AUTOSAR XML (schema 00048)
package /AUTOLIV/SoftwareComponents/PRE
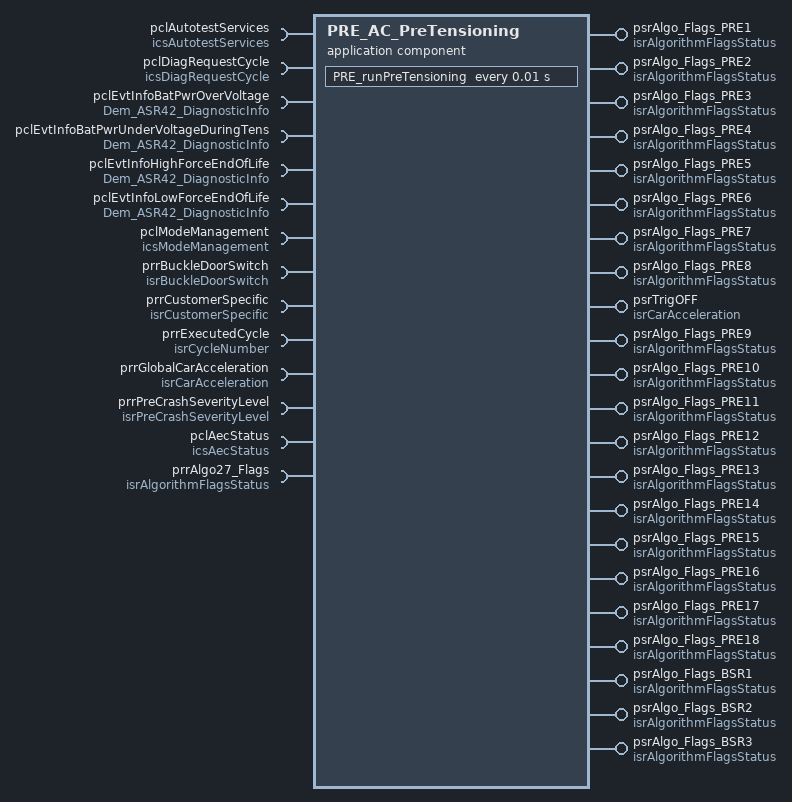
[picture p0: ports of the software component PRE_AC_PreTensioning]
  application sw component type PRE_AC_PreTensioning
    12 x require port:
      pclAutotestServices: required-com-specs=[GetLastCriticalAutotestID, GetTestResult], required-interface=icsAutotestServices
      pclDiagRequestCycle: required-com-specs=[ClearDiagRequestCycle, GetDiagRequestCycle], required-interface=icsDiagRequestCycle
      pclEvtInfoBatPwrOverVoltage: required-interface=Dem_ASR42_DiagnosticInfo
        required-com-specs:
          GetDTCOfEvent
          GetDebouncingOfEvent
          GetEventExtendedDataRecord
          GetEventExtendedDataRecordEx
          GetEventFailed
          GetEventFreezeFrameData
          GetEventFreezeFrameDataEx
          GetEventStatus
          GetEventTested
          GetFaultDetectionCounter
      pclEvtInfoBatPwrUnderVoltageDuringTens: required-interface=Dem_ASR42_DiagnosticInfo
        required-com-specs:
          GetDTCOfEvent
          GetDebouncingOfEvent
          GetEventExtendedDataRecord
          GetEventExtendedDataRecordEx
          GetEventFailed
          GetEventFreezeFrameData
          GetEventFreezeFrameDataEx
          GetEventStatus
          GetEventTested
          GetFaultDetectionCounter
      pclEvtInfoHighForceEndOfLife: required-interface=Dem_ASR42_DiagnosticInfo
        required-com-specs:
          GetDTCOfEvent
          GetDebouncingOfEvent
          GetEventExtendedDataRecord
          GetEventExtendedDataRecordEx
          GetEventFailed
          GetEventFreezeFrameData
          GetEventFreezeFrameDataEx
          GetEventStatus
          GetEventTested
          GetFaultDetectionCounter
      pclEvtInfoLowForceEndOfLife: required-interface=Dem_ASR42_DiagnosticInfo
        required-com-specs:
          GetDTCOfEvent
          GetDebouncingOfEvent
          GetEventExtendedDataRecord
          GetEventExtendedDataRecordEx
          GetEventFailed
          GetEventFreezeFrameData
          GetEventFreezeFrameDataEx
          GetEventStatus
          GetEventTested
          GetFaultDetectionCounter
      pclModeManagement: client-com-spec=CheckModeStatus, required-interface=icsModeManagement
      prrBuckleDoorSwitch: required-interface=isrBuckleDoorSwitch
        required-com-specs:
          data-element=u8BuckleSwitch, init-value=constant-reference=APPLINIT_KB8_BUCKLE_SWITCH_CLOSED
          data-element=u8DoorSwitch, init-value=constant-reference=APPLINIT_KU8_DOOR_SWITCH_STATUS_NOT_DEFINED
      prrCustomerSpecific: required-interface=isrCustomerSpecific
        required-com-specs:
          data-element=b8HardReleaseRequest
          data-element=b8IsCarCrankingActive, init-value=constant-reference=APPLINIT_KB8_CAR_CRANKING_ACTIVE_TRUE
          data-element=b8IsCarCrashDetected, init-value=constant-reference=APPLINIT_KB8_CAR_CRASH_DETECTED_FALSE
          data-element=b8IsTrigOffEventAllowed
          data-element=b8PreCrashRequestEnable, init-value=constant-reference=APPLINIT_KB8_BOOLEAN_FALSE
          data-element=u8BeltSlackStatus, init-value=constant-reference=APPLINIT_KU8_BELT_SLACK_STATUS_NOT_DEFINED
          data-element=u8HapticRequest, init-value=constant-reference=APPLINIT_KU8_HAPTIC_REQUEST_NO
          data-element=u8PreCrashRequest, init-value=constant-reference=APPLINIT_KU8_PRE_CRASH_REQUEST_NO_REQUEST
          data-element=u8TriggerRequest
          data-element=b8SignalRelInhibition
      prrExecutedCycle: nonqueued-receiver-com-spec{data-element=u8CycleNumber, init-value=constant-reference=APPLINIT_KU8_CYCLE_NUMBER_NONE}, required-interface=isrCycleNumber
      prrGlobalCarAcceleration: nonqueued-receiver-com-spec{data-element=b8IsCarAccelerationLow, init-value=constant-reference=APPLINIT_KB8_CAR_ACCEL_LOW_TRUE}, required-interface=isrCarAcceleration
      prrPreCrashSeverityLevel: nonqueued-receiver-com-spec{data-element=u8PreCrashSeverityLevel, init-value=constant-reference=APPLINIT_KU8_PRE_CRASH_SEVERITY_LEVEL_NO}, required-interface=isrPreCrashSeverityLevel
    9 x provide port:
      psrAlgo_Flags_PRE1: provided-interface=isrAlgorithmFlagsStatus
        provided-com-specs:
          data-element=b8InterruptFlag, init-value=constant-reference=APPLINIT_KB8_ALGO_FLAG_FALSE
          data-element=b8PreActivationFlag, uses-end-to-end-protection=true, init-value=constant-reference=APPLINIT_KB8_ALGO_FLAG_FALSE
          data-element=b8PreConditionsFlag, uses-end-to-end-protection=true, init-value=constant-reference=APPLINIT_KB8_ALGO_FLAG_FALSE
          data-element=b8TriggerFlag, uses-end-to-end-protection=true, init-value=constant-reference=APPLINIT_KB8_ALGO_FLAG_FALSE
          data-element=u8TriggeringSource, uses-end-to-end-protection=true, init-value=constant-reference=APPLINIT_KU8_TRIGGERING_SOURCE_NO
      psrAlgo_Flags_PRE2: provided-interface=isrAlgorithmFlagsStatus
        provided-com-specs:
          data-element=b8InterruptFlag, uses-end-to-end-protection=true, init-value=constant-reference=APPLINIT_KB8_ALGO_FLAG_FALSE
          data-element=b8PreActivationFlag, uses-end-to-end-protection=true, init-value=constant-reference=APPLINIT_KB8_ALGO_FLAG_FALSE
          data-element=b8PreConditionsFlag, uses-end-to-end-protection=true, init-value=constant-reference=APPLINIT_KB8_ALGO_FLAG_FALSE
          data-element=b8TriggerFlag, uses-end-to-end-protection=true, init-value=constant-reference=APPLINIT_KB8_ALGO_FLAG_FALSE
          data-element=u8TriggeringSource, uses-end-to-end-protection=true, init-value=constant-reference=APPLINIT_KU8_TRIGGERING_SOURCE_NO
      psrAlgo_Flags_PRE3: provided-interface=isrAlgorithmFlagsStatus
        provided-com-specs:
          data-element=b8InterruptFlag, uses-end-to-end-protection=true, init-value=constant-reference=APPLINIT_KB8_ALGO_FLAG_FALSE
          data-element=b8PreActivationFlag, uses-end-to-end-protection=true, init-value=constant-reference=APPLINIT_KB8_ALGO_FLAG_FALSE
          data-element=b8PreConditionsFlag, uses-end-to-end-protection=true, init-value=constant-reference=APPLINIT_KB8_ALGO_FLAG_FALSE
          data-element=b8TriggerFlag, uses-end-to-end-protection=true, init-value=constant-reference=APPLINIT_KB8_ALGO_FLAG_FALSE
          data-element=u8TriggeringSource, uses-end-to-end-protection=true, init-value=constant-reference=APPLINIT_KU8_TRIGGERING_SOURCE_NO
      psrAlgo_Flags_PRE4: provided-interface=isrAlgorithmFlagsStatus
        provided-com-specs:
          data-element=b8InterruptFlag, uses-end-to-end-protection=true, init-value=constant-reference=APPLINIT_KB8_ALGO_FLAG_FALSE
          data-element=b8PreActivationFlag, uses-end-to-end-protection=true, init-value=constant-reference=APPLINIT_KB8_ALGO_FLAG_FALSE
          data-element=b8PreConditionsFlag, uses-end-to-end-protection=true, init-value=constant-reference=APPLINIT_KB8_ALGO_FLAG_FALSE
          data-element=b8TriggerFlag, uses-end-to-end-protection=true, init-value=constant-reference=APPLINIT_KB8_ALGO_FLAG_FALSE
          data-element=u8TriggeringSource, uses-end-to-end-protection=true, init-value=constant-reference=APPLINIT_KU8_TRIGGERING_SOURCE_NO
      psrAlgo_Flags_PRE5: provided-interface=isrAlgorithmFlagsStatus
        provided-com-specs:
          data-element=b8InterruptFlag, uses-end-to-end-protection=true, init-value=constant-reference=APPLINIT_KB8_ALGO_FLAG_FALSE
          data-element=b8PreActivationFlag, uses-end-to-end-protection=true, init-value=constant-reference=APPLINIT_KB8_ALGO_FLAG_FALSE
          data-element=b8PreConditionsFlag, uses-end-to-end-protection=true, init-value=constant-reference=APPLINIT_KB8_ALGO_FLAG_FALSE
          data-element=b8TriggerFlag, uses-end-to-end-protection=true, init-value=constant-reference=APPLINIT_KB8_ALGO_FLAG_FALSE
          data-element=u8TriggeringSource, uses-end-to-end-protection=true, init-value=constant-reference=APPLINIT_KU8_TRIGGERING_SOURCE_NO
      psrAlgo_Flags_PRE6: provided-interface=isrAlgorithmFlagsStatus
        provided-com-specs:
          data-element=b8InterruptFlag, uses-end-to-end-protection=true, init-value=constant-reference=APPLINIT_KB8_ALGO_FLAG_FALSE
          data-element=b8PreActivationFlag, uses-end-to-end-protection=true, init-value=constant-reference=APPLINIT_KB8_ALGO_FLAG_FALSE
          data-element=b8PreConditionsFlag, uses-end-to-end-protection=true, init-value=constant-reference=APPLINIT_KB8_ALGO_FLAG_FALSE
          data-element=b8TriggerFlag, uses-end-to-end-protection=true, init-value=constant-reference=APPLINIT_KB8_ALGO_FLAG_FALSE
          data-element=u8TriggeringSource, uses-end-to-end-protection=true, init-value=constant-reference=APPLINIT_KU8_TRIGGERING_SOURCE_NO
      psrAlgo_Flags_PRE7: provided-interface=isrAlgorithmFlagsStatus
        provided-com-specs:
          data-element=b8InterruptFlag, uses-end-to-end-protection=true, init-value=constant-reference=APPLINIT_KB8_ALGO_FLAG_FALSE
          data-element=b8PreActivationFlag, uses-end-to-end-protection=true, init-value=constant-reference=APPLINIT_KB8_ALGO_FLAG_FALSE
          data-element=b8PreConditionsFlag, uses-end-to-end-protection=true, init-value=constant-reference=APPLINIT_KB8_ALGO_FLAG_FALSE
          data-element=b8TriggerFlag, uses-end-to-end-protection=true, init-value=constant-reference=APPLINIT_KB8_ALGO_FLAG_FALSE
          data-element=u8TriggeringSource, uses-end-to-end-protection=true, init-value=constant-reference=APPLINIT_KU8_TRIGGERING_SOURCE_NO
      psrAlgo_Flags_PRE8: provided-interface=isrAlgorithmFlagsStatus
        provided-com-specs:
          data-element=b8InterruptFlag, uses-end-to-end-protection=true, init-value=constant-reference=APPLINIT_KB8_ALGO_FLAG_FALSE
          data-element=b8PreActivationFlag, uses-end-to-end-protection=true, init-value=constant-reference=APPLINIT_KB8_ALGO_FLAG_FALSE
          data-element=b8PreConditionsFlag, uses-end-to-end-protection=true, init-value=constant-reference=APPLINIT_KB8_ALGO_FLAG_FALSE
          data-element=b8TriggerFlag, uses-end-to-end-protection=true, init-value=constant-reference=APPLINIT_KB8_ALGO_FLAG_FALSE
          data-element=u8TriggeringSource, uses-end-to-end-protection=true, init-value=constant-reference=APPLINIT_KU8_TRIGGERING_SOURCE_NO
      psrTrigOFF: nonqueued-sender-com-spec{data-element=b8IsCarAccelerationLow, uses-end-to-end-protection=true, init-value=constant-reference=APPLINIT_KB8_CAR_ACCEL_LOW_TRUE}, provided-interface=isrCarAcceleration
    require port pclAecStatus: required-interface=icsAecStatus
      required-com-specs:
        SetAecEvent
        GetNumberOfImplementedAec
        GetAecStatus
        GetAecQualificationCount
        GetAecNvpBlockRecordingStatus
        GetAecGroupsStatus
        GetAecDeskillThrs
    13 x provide port, all with provided-interface=isrAlgorithmFlagsStatus:
      psrAlgo_Flags_PRE9
        provided-com-specs:
          data-element=b8InterruptFlag, init-value=constant-reference=APPLINIT_KB8_ALGO_FLAG_FALSE
          data-element=b8PreActivationFlag, uses-end-to-end-protection=true, init-value=constant-reference=APPLINIT_KB8_ALGO_FLAG_FALSE
          data-element=b8PreConditionsFlag, uses-end-to-end-protection=true, init-value=constant-reference=APPLINIT_KB8_ALGO_FLAG_FALSE
          data-element=b8TriggerFlag, uses-end-to-end-protection=true, init-value=constant-reference=APPLINIT_KB8_ALGO_FLAG_FALSE
          data-element=u8TriggeringSource, uses-end-to-end-protection=true, init-value=constant-reference=APPLINIT_KU8_TRIGGERING_SOURCE_NO
      psrAlgo_Flags_PRE10
        provided-com-specs:
          data-element=b8InterruptFlag, uses-end-to-end-protection=true, init-value=constant-reference=APPLINIT_KB8_ALGO_FLAG_FALSE
          data-element=b8PreActivationFlag, uses-end-to-end-protection=true, init-value=constant-reference=APPLINIT_KB8_ALGO_FLAG_FALSE
          data-element=b8PreConditionsFlag, uses-end-to-end-protection=true, init-value=constant-reference=APPLINIT_KB8_ALGO_FLAG_FALSE
          data-element=b8TriggerFlag, uses-end-to-end-protection=true, init-value=constant-reference=APPLINIT_KB8_ALGO_FLAG_FALSE
          data-element=u8TriggeringSource, uses-end-to-end-protection=true, init-value=constant-reference=APPLINIT_KU8_TRIGGERING_SOURCE_NO
      psrAlgo_Flags_PRE11
        provided-com-specs:
          data-element=b8InterruptFlag, uses-end-to-end-protection=true, init-value=constant-reference=APPLINIT_KB8_ALGO_FLAG_FALSE
          data-element=b8PreActivationFlag, uses-end-to-end-protection=true, init-value=constant-reference=APPLINIT_KB8_ALGO_FLAG_FALSE
          data-element=b8PreConditionsFlag, uses-end-to-end-protection=true, init-value=constant-reference=APPLINIT_KB8_ALGO_FLAG_FALSE
          data-element=b8TriggerFlag, uses-end-to-end-protection=true, init-value=constant-reference=APPLINIT_KB8_ALGO_FLAG_FALSE
          data-element=u8TriggeringSource, uses-end-to-end-protection=true, init-value=constant-reference=APPLINIT_KU8_TRIGGERING_SOURCE_NO
      psrAlgo_Flags_PRE12
        provided-com-specs:
          data-element=b8InterruptFlag, uses-end-to-end-protection=true, init-value=constant-reference=APPLINIT_KB8_ALGO_FLAG_FALSE
          data-element=b8PreActivationFlag, uses-end-to-end-protection=true, init-value=constant-reference=APPLINIT_KB8_ALGO_FLAG_FALSE
          data-element=b8PreConditionsFlag, uses-end-to-end-protection=true, init-value=constant-reference=APPLINIT_KB8_ALGO_FLAG_FALSE
          data-element=b8TriggerFlag, uses-end-to-end-protection=true, init-value=constant-reference=APPLINIT_KB8_ALGO_FLAG_FALSE
          data-element=u8TriggeringSource, uses-end-to-end-protection=true, init-value=constant-reference=APPLINIT_KU8_TRIGGERING_SOURCE_NO
      psrAlgo_Flags_PRE13
        provided-com-specs:
          data-element=b8InterruptFlag, uses-end-to-end-protection=true, init-value=constant-reference=APPLINIT_KB8_ALGO_FLAG_FALSE
          data-element=b8PreActivationFlag, uses-end-to-end-protection=true, init-value=constant-reference=APPLINIT_KB8_ALGO_FLAG_FALSE
          data-element=b8PreConditionsFlag, uses-end-to-end-protection=true, init-value=constant-reference=APPLINIT_KB8_ALGO_FLAG_FALSE
          data-element=b8TriggerFlag, uses-end-to-end-protection=true, init-value=constant-reference=APPLINIT_KB8_ALGO_FLAG_FALSE
          data-element=u8TriggeringSource, uses-end-to-end-protection=true, init-value=constant-reference=APPLINIT_KU8_TRIGGERING_SOURCE_NO
      psrAlgo_Flags_PRE14
        provided-com-specs:
          data-element=b8InterruptFlag, uses-end-to-end-protection=true, init-value=constant-reference=APPLINIT_KB8_ALGO_FLAG_FALSE
          data-element=b8PreActivationFlag, uses-end-to-end-protection=true, init-value=constant-reference=APPLINIT_KB8_ALGO_FLAG_FALSE
          data-element=b8PreConditionsFlag, uses-end-to-end-protection=true, init-value=constant-reference=APPLINIT_KB8_ALGO_FLAG_FALSE
          data-element=b8TriggerFlag, uses-end-to-end-protection=true, init-value=constant-reference=APPLINIT_KB8_ALGO_FLAG_FALSE
          data-element=u8TriggeringSource, uses-end-to-end-protection=true, init-value=constant-reference=APPLINIT_KU8_TRIGGERING_SOURCE_NO
      psrAlgo_Flags_PRE15
        provided-com-specs:
          data-element=b8InterruptFlag, uses-end-to-end-protection=true, init-value=constant-reference=APPLINIT_KB8_ALGO_FLAG_FALSE
          data-element=b8PreActivationFlag, uses-end-to-end-protection=true, init-value=constant-reference=APPLINIT_KB8_ALGO_FLAG_FALSE
          data-element=b8PreConditionsFlag, uses-end-to-end-protection=true, init-value=constant-reference=APPLINIT_KB8_ALGO_FLAG_FALSE
          data-element=b8TriggerFlag, uses-end-to-end-protection=true, init-value=constant-reference=APPLINIT_KB8_ALGO_FLAG_FALSE
          data-element=u8TriggeringSource, uses-end-to-end-protection=true, init-value=constant-reference=APPLINIT_KU8_TRIGGERING_SOURCE_NO
      psrAlgo_Flags_PRE16
        provided-com-specs:
          data-element=b8InterruptFlag, uses-end-to-end-protection=true, init-value=constant-reference=APPLINIT_KB8_ALGO_FLAG_FALSE
          data-element=b8PreActivationFlag, uses-end-to-end-protection=true, init-value=constant-reference=APPLINIT_KB8_ALGO_FLAG_FALSE
          data-element=b8PreConditionsFlag, uses-end-to-end-protection=true, init-value=constant-reference=APPLINIT_KB8_ALGO_FLAG_FALSE
          data-element=b8TriggerFlag, uses-end-to-end-protection=true, init-value=constant-reference=APPLINIT_KB8_ALGO_FLAG_FALSE
          data-element=u8TriggeringSource, uses-end-to-end-protection=true, init-value=constant-reference=APPLINIT_KU8_TRIGGERING_SOURCE_NO
      psrAlgo_Flags_PRE17
        provided-com-specs:
          data-element=b8InterruptFlag, uses-end-to-end-protection=true, init-value=constant-reference=APPLINIT_KB8_ALGO_FLAG_FALSE
          data-element=b8PreActivationFlag, uses-end-to-end-protection=true, init-value=constant-reference=APPLINIT_KB8_ALGO_FLAG_FALSE
          data-element=b8PreConditionsFlag, uses-end-to-end-protection=true, init-value=constant-reference=APPLINIT_KB8_ALGO_FLAG_FALSE
          data-element=b8TriggerFlag, uses-end-to-end-protection=true, init-value=constant-reference=APPLINIT_KB8_ALGO_FLAG_FALSE
          data-element=u8TriggeringSource, uses-end-to-end-protection=true, init-value=constant-reference=APPLINIT_KU8_TRIGGERING_SOURCE_NO
      psrAlgo_Flags_PRE18
        provided-com-specs:
          data-element=b8InterruptFlag, uses-end-to-end-protection=true, init-value=constant-reference=APPLINIT_KB8_ALGO_FLAG_FALSE
          data-element=b8PreActivationFlag, uses-end-to-end-protection=true, init-value=constant-reference=APPLINIT_KB8_ALGO_FLAG_FALSE
          data-element=b8PreConditionsFlag, uses-end-to-end-protection=true, init-value=constant-reference=APPLINIT_KB8_ALGO_FLAG_FALSE
          data-element=b8TriggerFlag, uses-end-to-end-protection=true, init-value=constant-reference=APPLINIT_KB8_ALGO_FLAG_FALSE
          data-element=u8TriggeringSource, uses-end-to-end-protection=true, init-value=constant-reference=APPLINIT_KU8_TRIGGERING_SOURCE_NO
      psrAlgo_Flags_BSR1
        provided-com-specs:
          data-element=b8InterruptFlag, init-value=constant-reference=APPLINIT_KB8_ALGO_FLAG_FALSE
          data-element=b8PreActivationFlag, init-value=constant-reference=APPLINIT_KB8_ALGO_FLAG_FALSE
          data-element=b8PreConditionsFlag, init-value=constant-reference=APPLINIT_KB8_ALGO_FLAG_FALSE
          data-element=b8TriggerFlag, init-value=constant-reference=APPLINIT_KB8_ALGO_FLAG_FALSE
          data-element=u8TriggeringSource, init-value=constant-reference=APPLINIT_KU8_TRIGGERING_SOURCE_NO
      psrAlgo_Flags_BSR2
        provided-com-specs:
          data-element=b8InterruptFlag, uses-end-to-end-protection=true, init-value=constant-reference=APPLINIT_KB8_ALGO_FLAG_FALSE
          data-element=b8PreActivationFlag, uses-end-to-end-protection=true, init-value=constant-reference=APPLINIT_KB8_ALGO_FLAG_FALSE
          data-element=b8PreConditionsFlag, uses-end-to-end-protection=true, init-value=constant-reference=APPLINIT_KB8_ALGO_FLAG_FALSE
          data-element=b8TriggerFlag, uses-end-to-end-protection=true, init-value=constant-reference=APPLINIT_KB8_ALGO_FLAG_FALSE
          data-element=u8TriggeringSource, uses-end-to-end-protection=true, init-value=constant-reference=APPLINIT_KU8_TRIGGERING_SOURCE_NO
      psrAlgo_Flags_BSR3
        provided-com-specs:
          data-element=b8InterruptFlag, uses-end-to-end-protection=true, init-value=constant-reference=APPLINIT_KB8_ALGO_FLAG_FALSE
          data-element=b8PreActivationFlag, uses-end-to-end-protection=true, init-value=constant-reference=APPLINIT_KB8_ALGO_FLAG_FALSE
          data-element=b8PreConditionsFlag, uses-end-to-end-protection=true, init-value=constant-reference=APPLINIT_KB8_ALGO_FLAG_FALSE
          data-element=b8TriggerFlag, uses-end-to-end-protection=true, init-value=constant-reference=APPLINIT_KB8_ALGO_FLAG_FALSE
          data-element=u8TriggeringSource, uses-end-to-end-protection=true, init-value=constant-reference=APPLINIT_KU8_TRIGGERING_SOURCE_NO
    require port prrAlgo27_Flags: required-interface=isrAlgorithmFlagsStatus
      required-com-specs:
        data-element=b8InterruptFlag, init-value=constant-reference=APPLINIT_KB8_ALGO_FLAG_FALSE
        data-element=b8PreActivationFlag, init-value=constant-reference=APPLINIT_KB8_ALGO_FLAG_FALSE
        data-element=b8PreConditionsFlag, init-value=constant-reference=APPLINIT_KB8_ALGO_FLAG_FALSE
        data-element=b8TriggerFlag, init-value=constant-reference=APPLINIT_KB8_ALGO_FLAG_FALSE
        data-element=u8TriggeringSource, init-value=constant-reference=APPLINIT_KU8_TRIGGERING_SOURCE_NO
    behavior PRE_IB_PreTensioning: data-type-mapping=DataTypeMappingSet_PP4G
      timing event PRE_evPreTensioning: start-on-event=PRE_runPreTensioning, period=0.01
      runnable PRE_runPreTensioning
        data-receive-point-by-arguments:
          11 x access:
            DRP_prrBuckleDoorSwitch_u8BuckleSwitch: accessed-variable=prrBuckleDoorSwitch.u8BuckleSwitch
            DRP_prrCustomerSpecific_b8IsCarCrashDetected: accessed-variable=prrCustomerSpecific.b8IsCarCrashDetected
            DRP_prrCustomerSpecific_b8PreCrashRequestEnable: accessed-variable=prrCustomerSpecific.b8PreCrashRequestEnable
            DRP_prrExecutedCycle_u8CycleNumber: accessed-variable=prrExecutedCycle.u8CycleNumber
            DRP_prrGlobalCarAcceleration_b8IsCarAccelerationLow: accessed-variable=prrGlobalCarAcceleration.b8IsCarAccelerationLow
            DRP_prrPreCrashSeverityLevel_u8PreCrashSeverityLevel: accessed-variable=prrPreCrashSeverityLevel.u8PreCrashSeverityLevel
            REC_prrAlgo27_Flags_b8InterruptFlag: accessed-variable=prrAlgo27_Flags.b8InterruptFlag
            REC_prrAlgo27_Flags_b8PreActivationFlag: accessed-variable=prrAlgo27_Flags.b8PreActivationFlag
            REC_prrAlgo27_Flags_b8PreConditionsFlag: accessed-variable=prrAlgo27_Flags.b8PreConditionsFlag
            REC_prrAlgo27_Flags_b8TriggerFlag: accessed-variable=prrAlgo27_Flags.b8TriggerFlag
            REC_prrAlgo27_Flags_u8TriggeringSource: accessed-variable=prrAlgo27_Flags.u8TriggeringSource
        data-send-points:
          106 x access:
            DSP_psrAlgo_Flags_PRE1_b8InterruptFlag: accessed-variable=psrAlgo_Flags_PRE1.b8InterruptFlag
            DSP_psrAlgo_Flags_PRE1_b8PreActivationFlag: accessed-variable=psrAlgo_Flags_PRE1.b8PreActivationFlag
            DSP_psrAlgo_Flags_PRE1_b8PreConditionsFlag: accessed-variable=psrAlgo_Flags_PRE1.b8PreConditionsFlag
            DSP_psrAlgo_Flags_PRE1_b8TriggerFlag: accessed-variable=psrAlgo_Flags_PRE1.b8TriggerFlag
            DSP_psrAlgo_Flags_PRE1_u8TriggeringSource: accessed-variable=psrAlgo_Flags_PRE1.u8TriggeringSource
            DSP_psrAlgo_Flags_PRE2_b8InterruptFlag: accessed-variable=psrAlgo_Flags_PRE2.b8InterruptFlag
            DSP_psrAlgo_Flags_PRE2_b8PreActivationFlag: accessed-variable=psrAlgo_Flags_PRE2.b8PreActivationFlag
            DSP_psrAlgo_Flags_PRE2_b8PreConditionsFlag: accessed-variable=psrAlgo_Flags_PRE2.b8PreConditionsFlag
            DSP_psrAlgo_Flags_PRE2_b8TriggerFlag: accessed-variable=psrAlgo_Flags_PRE2.b8TriggerFlag
            DSP_psrAlgo_Flags_PRE2_u8TriggeringSource: accessed-variable=psrAlgo_Flags_PRE2.u8TriggeringSource
            DSP_psrAlgo_Flags_PRE3_b8InterruptFlag: accessed-variable=psrAlgo_Flags_PRE3.b8InterruptFlag
            DSP_psrAlgo_Flags_PRE3_b8PreActivationFlag: accessed-variable=psrAlgo_Flags_PRE3.b8PreActivationFlag
            DSP_psrAlgo_Flags_PRE3_b8PreConditionsFlag: accessed-variable=psrAlgo_Flags_PRE3.b8PreConditionsFlag
            DSP_psrAlgo_Flags_PRE3_b8TriggerFlag: accessed-variable=psrAlgo_Flags_PRE3.b8TriggerFlag
            DSP_psrAlgo_Flags_PRE3_u8TriggeringSource: accessed-variable=psrAlgo_Flags_PRE3.u8TriggeringSource
            DSP_psrAlgo_Flags_PRE4_b8InterruptFlag: accessed-variable=psrAlgo_Flags_PRE4.b8InterruptFlag
            DSP_psrAlgo_Flags_PRE4_b8PreActivationFlag: accessed-variable=psrAlgo_Flags_PRE4.b8PreActivationFlag
            DSP_psrAlgo_Flags_PRE4_b8PreConditionsFlag: accessed-variable=psrAlgo_Flags_PRE4.b8PreConditionsFlag
            DSP_psrAlgo_Flags_PRE4_b8TriggerFlag: accessed-variable=psrAlgo_Flags_PRE4.b8TriggerFlag
            DSP_psrAlgo_Flags_PRE4_u8TriggeringSource: accessed-variable=psrAlgo_Flags_PRE4.u8TriggeringSource
            DSP_psrAlgo_Flags_PRE5_b8InterruptFlag: accessed-variable=psrAlgo_Flags_PRE5.b8InterruptFlag
            DSP_psrAlgo_Flags_PRE5_b8PreActivationFlag: accessed-variable=psrAlgo_Flags_PRE5.b8PreActivationFlag
            DSP_psrAlgo_Flags_PRE5_b8PreConditionsFlag: accessed-variable=psrAlgo_Flags_PRE5.b8PreConditionsFlag
            DSP_psrAlgo_Flags_PRE5_b8TriggerFlag: accessed-variable=psrAlgo_Flags_PRE5.b8TriggerFlag
            DSP_psrAlgo_Flags_PRE5_u8TriggeringSource: accessed-variable=psrAlgo_Flags_PRE5.u8TriggeringSource
            DSP_psrAlgo_Flags_PRE6_b8InterruptFlag: accessed-variable=psrAlgo_Flags_PRE6.b8InterruptFlag
            DSP_psrAlgo_Flags_PRE6_b8PreActivationFlag: accessed-variable=psrAlgo_Flags_PRE6.b8PreActivationFlag
            DSP_psrAlgo_Flags_PRE6_b8PreConditionsFlag: accessed-variable=psrAlgo_Flags_PRE6.b8PreConditionsFlag
            DSP_psrAlgo_Flags_PRE6_b8TriggerFlag: accessed-variable=psrAlgo_Flags_PRE6.b8TriggerFlag
            DSP_psrAlgo_Flags_PRE6_u8TriggeringSource: accessed-variable=psrAlgo_Flags_PRE6.u8TriggeringSource
            DSP_psrAlgo_Flags_PRE7_b8InterruptFlag: accessed-variable=psrAlgo_Flags_PRE7.b8InterruptFlag
            DSP_psrAlgo_Flags_PRE7_b8PreActivationFlag: accessed-variable=psrAlgo_Flags_PRE7.b8PreActivationFlag
            DSP_psrAlgo_Flags_PRE7_b8PreConditionsFlag: accessed-variable=psrAlgo_Flags_PRE7.b8PreConditionsFlag
            DSP_psrAlgo_Flags_PRE7_b8TriggerFlag: accessed-variable=psrAlgo_Flags_PRE7.b8TriggerFlag
            DSP_psrAlgo_Flags_PRE7_u8TriggeringSource: accessed-variable=psrAlgo_Flags_PRE7.u8TriggeringSource
            DSP_psrAlgo_Flags_PRE8_b8InterruptFlag: accessed-variable=psrAlgo_Flags_PRE8.b8InterruptFlag
            DSP_psrAlgo_Flags_PRE8_b8PreActivationFlag: accessed-variable=psrAlgo_Flags_PRE8.b8PreActivationFlag
            DSP_psrAlgo_Flags_PRE8_b8PreConditionsFlag: accessed-variable=psrAlgo_Flags_PRE8.b8PreConditionsFlag
            DSP_psrAlgo_Flags_PRE8_b8TriggerFlag: accessed-variable=psrAlgo_Flags_PRE8.b8TriggerFlag
            DSP_psrAlgo_Flags_PRE8_u8TriggeringSource: accessed-variable=psrAlgo_Flags_PRE8.u8TriggeringSource
            DSP_psrTrigOFF_b8IsCarAccelerationLow: accessed-variable=psrTrigOFF.b8IsCarAccelerationLow
            SEND_psrAlgo_Flags_PRE10_b8InterruptFlag: accessed-variable=psrAlgo_Flags_PRE10.b8InterruptFlag
            SEND_psrAlgo_Flags_PRE10_b8PreActivationFlag: accessed-variable=psrAlgo_Flags_PRE10.b8PreActivationFlag
            SEND_psrAlgo_Flags_PRE10_b8PreConditionsFlag: accessed-variable=psrAlgo_Flags_PRE10.b8PreConditionsFlag
            SEND_psrAlgo_Flags_PRE10_b8TriggerFlag: accessed-variable=psrAlgo_Flags_PRE10.b8TriggerFlag
            SEND_psrAlgo_Flags_PRE10_u8TriggeringSource: accessed-variable=psrAlgo_Flags_PRE10.u8TriggeringSource
            SEND_psrAlgo_Flags_PRE11_b8InterruptFlag: accessed-variable=psrAlgo_Flags_PRE11.b8InterruptFlag
            SEND_psrAlgo_Flags_PRE11_b8PreActivationFlag: accessed-variable=psrAlgo_Flags_PRE11.b8PreActivationFlag
            SEND_psrAlgo_Flags_PRE11_b8PreConditionsFlag: accessed-variable=psrAlgo_Flags_PRE11.b8PreConditionsFlag
            SEND_psrAlgo_Flags_PRE11_b8TriggerFlag: accessed-variable=psrAlgo_Flags_PRE11.b8TriggerFlag
            SEND_psrAlgo_Flags_PRE11_u8TriggeringSource: accessed-variable=psrAlgo_Flags_PRE11.u8TriggeringSource
            SEND_psrAlgo_Flags_PRE12_b8InterruptFlag: accessed-variable=psrAlgo_Flags_PRE12.b8InterruptFlag
            SEND_psrAlgo_Flags_PRE12_b8PreActivationFlag: accessed-variable=psrAlgo_Flags_PRE12.b8PreActivationFlag
            SEND_psrAlgo_Flags_PRE12_b8PreConditionsFlag: accessed-variable=psrAlgo_Flags_PRE12.b8PreConditionsFlag
            SEND_psrAlgo_Flags_PRE12_b8TriggerFlag: accessed-variable=psrAlgo_Flags_PRE12.b8TriggerFlag
            SEND_psrAlgo_Flags_PRE12_u8TriggeringSource: accessed-variable=psrAlgo_Flags_PRE12.u8TriggeringSource
            SEND_psrAlgo_Flags_PRE13_b8InterruptFlag: accessed-variable=psrAlgo_Flags_PRE13.b8InterruptFlag
            SEND_psrAlgo_Flags_PRE13_b8PreActivationFlag: accessed-variable=psrAlgo_Flags_PRE13.b8PreActivationFlag
            SEND_psrAlgo_Flags_PRE13_b8PreConditionsFlag: accessed-variable=psrAlgo_Flags_PRE13.b8PreConditionsFlag
            SEND_psrAlgo_Flags_PRE13_b8TriggerFlag: accessed-variable=psrAlgo_Flags_PRE13.b8TriggerFlag
            SEND_psrAlgo_Flags_PRE13_u8TriggeringSource: accessed-variable=psrAlgo_Flags_PRE13.u8TriggeringSource
            SEND_psrAlgo_Flags_PRE14_b8InterruptFlag: accessed-variable=psrAlgo_Flags_PRE14.b8InterruptFlag
            SEND_psrAlgo_Flags_PRE14_b8PreActivationFlag: accessed-variable=psrAlgo_Flags_PRE14.b8PreActivationFlag
            SEND_psrAlgo_Flags_PRE14_b8PreConditionsFlag: accessed-variable=psrAlgo_Flags_PRE14.b8PreConditionsFlag
            SEND_psrAlgo_Flags_PRE14_b8TriggerFlag: accessed-variable=psrAlgo_Flags_PRE14.b8TriggerFlag
            SEND_psrAlgo_Flags_PRE14_u8TriggeringSource: accessed-variable=psrAlgo_Flags_PRE14.u8TriggeringSource
            SEND_psrAlgo_Flags_PRE15_b8InterruptFlag: accessed-variable=psrAlgo_Flags_PRE15.b8InterruptFlag
            SEND_psrAlgo_Flags_PRE15_b8PreActivationFlag: accessed-variable=psrAlgo_Flags_PRE15.b8PreActivationFlag
            SEND_psrAlgo_Flags_PRE15_b8PreConditionsFlag: accessed-variable=psrAlgo_Flags_PRE15.b8PreConditionsFlag
            SEND_psrAlgo_Flags_PRE15_b8TriggerFlag: accessed-variable=psrAlgo_Flags_PRE15.b8TriggerFlag
            SEND_psrAlgo_Flags_PRE15_u8TriggeringSource: accessed-variable=psrAlgo_Flags_PRE15.u8TriggeringSource
            SEND_psrAlgo_Flags_PRE16_b8InterruptFlag: accessed-variable=psrAlgo_Flags_PRE16.b8InterruptFlag
            SEND_psrAlgo_Flags_PRE16_b8PreActivationFlag: accessed-variable=psrAlgo_Flags_PRE16.b8PreActivationFlag
            SEND_psrAlgo_Flags_PRE16_b8PreConditionsFlag: accessed-variable=psrAlgo_Flags_PRE16.b8PreConditionsFlag
            SEND_psrAlgo_Flags_PRE16_b8TriggerFlag: accessed-variable=psrAlgo_Flags_PRE16.b8TriggerFlag
            SEND_psrAlgo_Flags_PRE16_u8TriggeringSource: accessed-variable=psrAlgo_Flags_PRE16.u8TriggeringSource
            SEND_psrAlgo_Flags_PRE17_b8InterruptFlag: accessed-variable=psrAlgo_Flags_PRE17.b8InterruptFlag
            SEND_psrAlgo_Flags_PRE17_b8PreActivationFlag: accessed-variable=psrAlgo_Flags_PRE17.b8PreActivationFlag
            SEND_psrAlgo_Flags_PRE17_b8PreConditionsFlag: accessed-variable=psrAlgo_Flags_PRE17.b8PreConditionsFlag
            SEND_psrAlgo_Flags_PRE17_b8TriggerFlag: accessed-variable=psrAlgo_Flags_PRE17.b8TriggerFlag
            SEND_psrAlgo_Flags_PRE17_u8TriggeringSource: accessed-variable=psrAlgo_Flags_PRE17.u8TriggeringSource
            SEND_psrAlgo_Flags_PRE18_b8InterruptFlag: accessed-variable=psrAlgo_Flags_PRE18.b8InterruptFlag
            SEND_psrAlgo_Flags_PRE18_b8PreActivationFlag: accessed-variable=psrAlgo_Flags_PRE18.b8PreActivationFlag
            SEND_psrAlgo_Flags_PRE18_b8PreConditionsFlag: accessed-variable=psrAlgo_Flags_PRE18.b8PreConditionsFlag
            SEND_psrAlgo_Flags_PRE18_b8TriggerFlag: accessed-variable=psrAlgo_Flags_PRE18.b8TriggerFlag
            SEND_psrAlgo_Flags_PRE18_u8TriggeringSource: accessed-variable=psrAlgo_Flags_PRE18.u8TriggeringSource
            SEND_psrAlgo_Flags_PRE9_b8InterruptFlag: accessed-variable=psrAlgo_Flags_PRE9.b8InterruptFlag
            SEND_psrAlgo_Flags_PRE9_b8PreActivationFlag: accessed-variable=psrAlgo_Flags_PRE9.b8PreActivationFlag
            SEND_psrAlgo_Flags_PRE9_b8PreConditionsFlag: accessed-variable=psrAlgo_Flags_PRE9.b8PreConditionsFlag
            SEND_psrAlgo_Flags_PRE9_b8TriggerFlag: accessed-variable=psrAlgo_Flags_PRE9.b8TriggerFlag
            SEND_psrAlgo_Flags_PRE9_u8TriggeringSource: accessed-variable=psrAlgo_Flags_PRE9.u8TriggeringSource
            SEND_psrAlgo_Flags_BSR1_b8InterruptFlag: accessed-variable=psrAlgo_Flags_BSR1.b8InterruptFlag
            SEND_psrAlgo_Flags_BSR1_b8PreActivationFlag: accessed-variable=psrAlgo_Flags_BSR1.b8PreActivationFlag
            SEND_psrAlgo_Flags_BSR1_b8PreConditionsFlag: accessed-variable=psrAlgo_Flags_BSR1.b8PreConditionsFlag
            SEND_psrAlgo_Flags_BSR1_b8TriggerFlag: accessed-variable=psrAlgo_Flags_BSR1.b8TriggerFlag
            SEND_psrAlgo_Flags_BSR1_u8TriggeringSource: accessed-variable=psrAlgo_Flags_BSR1.u8TriggeringSource
            SEND_psrAlgo_Flags_BSR2_b8InterruptFlag: accessed-variable=psrAlgo_Flags_BSR2.b8InterruptFlag
            SEND_psrAlgo_Flags_BSR2_b8PreActivationFlag: accessed-variable=psrAlgo_Flags_BSR2.b8PreActivationFlag
            SEND_psrAlgo_Flags_BSR2_b8PreConditionsFlag: accessed-variable=psrAlgo_Flags_BSR2.b8PreConditionsFlag
            SEND_psrAlgo_Flags_BSR2_b8TriggerFlag: accessed-variable=psrAlgo_Flags_BSR2.b8TriggerFlag
            SEND_psrAlgo_Flags_BSR2_u8TriggeringSource: accessed-variable=psrAlgo_Flags_BSR2.u8TriggeringSource
            SEND_psrAlgo_Flags_BSR3_b8InterruptFlag: accessed-variable=psrAlgo_Flags_BSR3.b8InterruptFlag
            SEND_psrAlgo_Flags_BSR3_b8PreActivationFlag: accessed-variable=psrAlgo_Flags_BSR3.b8PreActivationFlag
            SEND_psrAlgo_Flags_BSR3_b8PreConditionsFlag: accessed-variable=psrAlgo_Flags_BSR3.b8PreConditionsFlag
            SEND_psrAlgo_Flags_BSR3_b8TriggerFlag: accessed-variable=psrAlgo_Flags_BSR3.b8TriggerFlag
            SEND_psrAlgo_Flags_BSR3_u8TriggeringSource: accessed-variable=psrAlgo_Flags_BSR3.u8TriggeringSource
        9 x sync call:
          SSCP_pclDiagRequestCycle_ClearDiagRequestCycle: operation=pclDiagRequestCycle.ClearDiagRequestCycle
          SSCP_pclDiagRequestCycle_GetDiagRequestCycle: operation=pclDiagRequestCycle.GetDiagRequestCycle
          SSCP_pclModeManagement_CheckModeStatus: operation=pclModeManagement.CheckModeStatus
          SSCP_pclTestResult_GetTestResult: operation=pclAutotestServices.GetTestResult
          scp_GetEventStatus: operation=pclEvtInfoBatPwrOverVoltage.GetEventStatus
          scp_GetEventStatus1: operation=pclEvtInfoHighForceEndOfLife.GetEventStatus
          scp_GetEventStatus2: operation=pclEvtInfoLowForceEndOfLife.GetEventStatus
          scp_GetEventStatus3: operation=pclEvtInfoBatPwrUnderVoltageDuringTens.GetEventStatus
          SC_pclAecStatus_GetAecStatus: operation=pclAecStatus.GetAecStatus
  swc implementation PRE_AC_PreTensioning_Implementation: behavior=PRE_IB_PreTensioning
